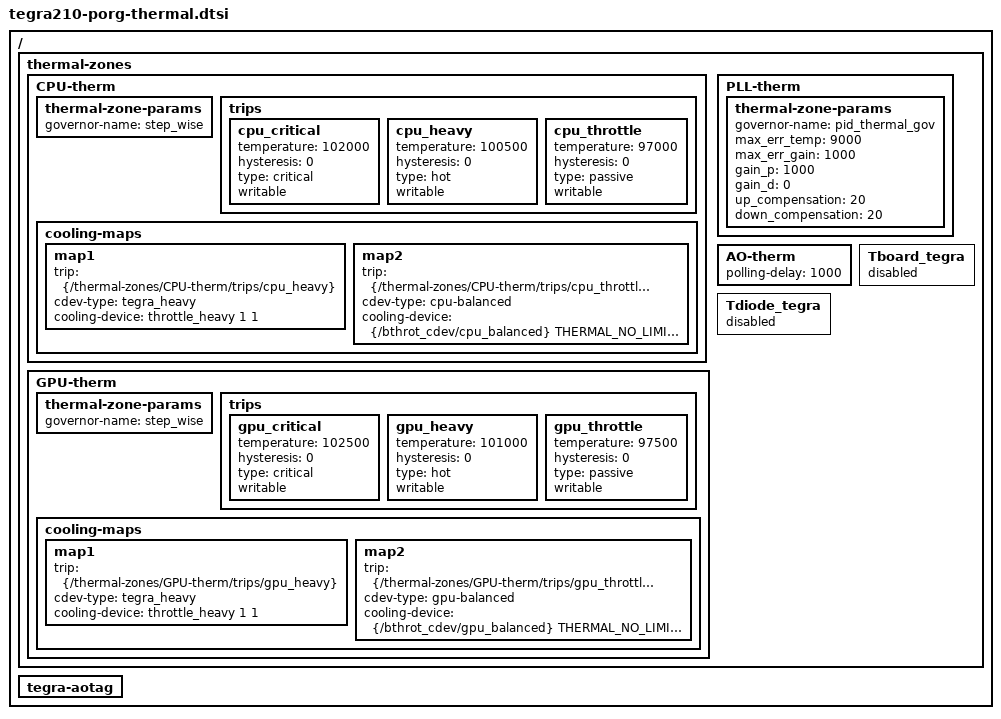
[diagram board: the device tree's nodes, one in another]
/*
 * Copyright (c) 2019, NVIDIA CORPORATION.  All rights reserved.
 *
 * This program is free software; you can redistribute it and/or modify it
 * under the terms and conditions of the GNU General Public License,
 * version 2, as published by the Free Software Foundation.
 *
 * This program is distributed in the hope it will be useful, but WITHOUT
 * ANY WARRANTY; without even the implied warranty of MERCHANTABILITY or
 * FITNESS FOR A PARTICULAR PURPOSE.  See the GNU General Public License for
 * more details.
 */

/ {
	thermal-zones {
		CPU-therm {
			thermal-zone-params {
				governor-name = "step_wise";
			};
			trips {
				cpu_critical {
					temperature = <102000>;
					hysteresis = <0>;
					type = "critical";
					writable;
				};
				cpu_heavy {
					temperature = <100500>;
					hysteresis = <0>;
					type = "hot";
					writable;
				};
				cpu_throttle {
					temperature = <97000>;
					hysteresis = <0>;
					type = "passive";
					writable;
				};
			};
			cooling-maps {
				/delete-node/ map0;
				map1 {
					trip = <&{/thermal-zones/CPU-therm/trips/cpu_heavy}>;
					cdev-type = "tegra_heavy";
					cooling-device = <&throttle_heavy 1 1>;
				};
				map2 {
					trip = <&{/thermal-zones/CPU-therm/trips/cpu_throttle}>;
					cdev-type = "cpu-balanced";
					cooling-device = <&{/bthrot_cdev/cpu_balanced}
						THERMAL_NO_LIMIT THERMAL_NO_LIMIT>;
				};
			};
		};
		/delete-node/ LCPU-therm;
		GPU-therm {
			thermal-zone-params {
				governor-name = "step_wise";
			};
			trips {
				gpu_critical {
					temperature = <102500>;
					hysteresis = <0>;
					type = "critical";
					writable;
				};
				gpu_heavy {
					temperature = <101000>;
					hysteresis = <0>;
					type = "hot";
					writable;
				};
				gpu_throttle {
					temperature = <97500>;
					hysteresis = <0>;
					type = "passive";
					writable;
				};
			};
			cooling-maps {
				/delete-node/ map0;
				map1 {
					trip = <&{/thermal-zones/GPU-therm/trips/gpu_heavy}>;
					cdev-type = "tegra_heavy";
					cooling-device = <&throttle_heavy 1 1>;
				};
				map2 {
					trip = <&{/thermal-zones/GPU-therm/trips/gpu_throttle}>;
					cdev-type = "gpu-balanced";
					cooling-device = <&{/bthrot_cdev/gpu_balanced}
						THERMAL_NO_LIMIT THERMAL_NO_LIMIT>;
				};
			};
		};
		PLL-therm {
			thermal-zone-params {
				governor-name = "pid_thermal_gov";
				max_err_temp = <9000>;
				max_err_gain = <1000>;
				gain_p = <1000>;
				gain_d = <0>;
				up_compensation = <20>;
				down_compensation = <20>;
			};
		};
		AO-therm {
			polling-delay = <1000>;
			status = "okay";
		};

		Tboard_tegra {
			status = "disabled";
		};

		Tdiode_tegra {
			status = "disabled";
		};
	};

	tegra-aotag {
		status = "okay";
	};
};
